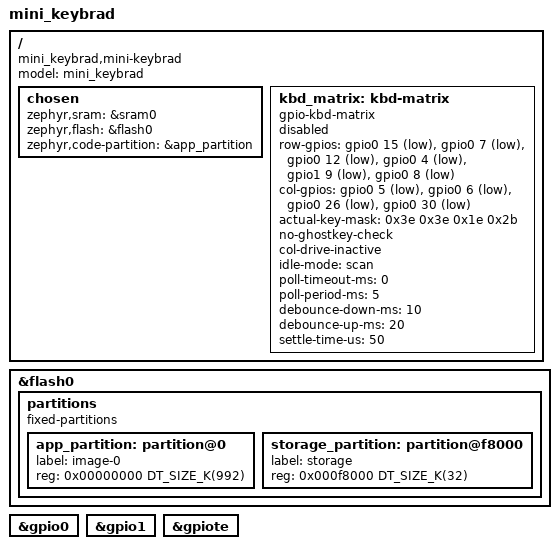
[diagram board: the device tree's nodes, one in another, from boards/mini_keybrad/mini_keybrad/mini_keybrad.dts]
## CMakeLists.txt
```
cmake_minimum_required(VERSION 3.20.0)

list(APPEND BOARD_ROOT "${CMAKE_CURRENT_SOURCE_DIR}")

find_package(Zephyr REQUIRED HINTS $ENV{ZEPHYR_BASE})

project(anjian1)

target_sources(app PRIVATE src/main.c)
```

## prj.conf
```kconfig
CONFIG_GPIO=y
CONFIG_INPUT=y
CONFIG_INPUT_MODE_SYNCHRONOUS=y

CONFIG_LOG=n
CONFIG_BOOT_BANNER=n
CONFIG_NCS_BOOT_BANNER=n
CONFIG_CONSOLE=y
CONFIG_USE_SEGGER_RTT=y
CONFIG_RTT_CONSOLE=y
CONFIG_LOG_BACKEND_UART=n
```

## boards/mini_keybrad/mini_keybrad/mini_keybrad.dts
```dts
/dts-v1/;
#include <nordic/nrf52840_qiaa.dtsi>
#include "mini_keybrad-pinctrl.dtsi"

/ {
	model = "mini_keybrad";
	compatible = "mini_keybrad,mini-keybrad";

	chosen {
		zephyr,sram = &sram0;
		zephyr,flash = &flash0;
		zephyr,code-partition = &app_partition;
	};

	kbd_matrix: kbd-matrix {
		compatible = "gpio-kbd-matrix";
		status = "disabled";

		/*
		 * Temporary pin mapping from the schematic:
		 * ROW0..ROW5: U36.28, U36.22, U36.20, U36.18, U36.17, U36.16
		 * COL0..COL3: U36.15, U36.14, U36.12, U36.10
		 *
		 * Adjust only these row-gpios/col-gpios entries if board bring-up
		 * shows a row or column mismatch.
		 */
		row-gpios = <&gpio0 15 (GPIO_PULL_UP | GPIO_ACTIVE_LOW)>,
			    <&gpio0 7  (GPIO_PULL_UP | GPIO_ACTIVE_LOW)>,
			    <&gpio0 12 (GPIO_PULL_UP | GPIO_ACTIVE_LOW)>,
			    <&gpio0 4  (GPIO_PULL_UP | GPIO_ACTIVE_LOW)>,
			    <&gpio1 9  (GPIO_PULL_UP | GPIO_ACTIVE_LOW)>,
			    <&gpio0 8  (GPIO_PULL_UP | GPIO_ACTIVE_LOW)>;

		col-gpios = <&gpio0 5  GPIO_ACTIVE_LOW>,
			    <&gpio0 6  GPIO_ACTIVE_LOW>,
			    <&gpio0 26 GPIO_ACTIVE_LOW>,
			    <&gpio0 30 GPIO_ACTIVE_LOW>;

		actual-key-mask = <0x3e 0x3e 0x1e 0x2b>;
		no-ghostkey-check;
		col-drive-inactive;
		idle-mode = "scan";
		poll-timeout-ms = <0>;
		poll-period-ms = <5>;
		debounce-down-ms = <10>;
		debounce-up-ms = <20>;
		settle-time-us = <50>;
	};
};

&flash0 {
	partitions {
		compatible = "fixed-partitions";
		#address-cells = <1>;
		#size-cells = <1>;

		app_partition: partition@0 {
			label = "image-0";
			reg = <0x00000000 DT_SIZE_K(992)>;
		};

		storage_partition: partition@f8000 {
			label = "storage";
			reg = <0x000f8000 DT_SIZE_K(32)>;
		};
	};
};

&gpio0 {
	status = "okay";
};

&gpio1 {
	status = "okay";
};

&gpiote {
	status = "okay";
};
```

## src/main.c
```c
#include <zephyr/device.h>
#include <zephyr/drivers/gpio.h>
#include <zephyr/kernel.h>
#include <zephyr/sys/printk.h>
#include <SEGGER_RTT.h>

#define ROW_COUNT 6
#define COL_COUNT 4

struct key_coord {
	uint8_t phys_row;
	uint8_t phys_col;
	uint8_t logical_row;
	uint8_t logical_col;
};

static const struct gpio_dt_spec rows[] = {
	GPIO_DT_SPEC_GET_BY_IDX(DT_NODELABEL(kbd_matrix), row_gpios, 0),
	GPIO_DT_SPEC_GET_BY_IDX(DT_NODELABEL(kbd_matrix), row_gpios, 1),
	GPIO_DT_SPEC_GET_BY_IDX(DT_NODELABEL(kbd_matrix), row_gpios, 2),
	GPIO_DT_SPEC_GET_BY_IDX(DT_NODELABEL(kbd_matrix), row_gpios, 3),
	GPIO_DT_SPEC_GET_BY_IDX(DT_NODELABEL(kbd_matrix), row_gpios, 4),
	GPIO_DT_SPEC_GET_BY_IDX(DT_NODELABEL(kbd_matrix), row_gpios, 5),
};

static const struct gpio_dt_spec cols[] = {
	GPIO_DT_SPEC_GET_BY_IDX(DT_NODELABEL(kbd_matrix), col_gpios, 0),
	GPIO_DT_SPEC_GET_BY_IDX(DT_NODELABEL(kbd_matrix), col_gpios, 1),
	GPIO_DT_SPEC_GET_BY_IDX(DT_NODELABEL(kbd_matrix), col_gpios, 2),
	GPIO_DT_SPEC_GET_BY_IDX(DT_NODELABEL(kbd_matrix), col_gpios, 3),
};

static const struct key_coord key_map[] = {
	{0, 3, 0, 0},
	{1, 0, 1, 0},
	{1, 1, 1, 1},
	{1, 2, 1, 2},
	{1, 3, 1, 3},
	{2, 0, 2, 0},
	{2, 1, 2, 1},
	{2, 2, 2, 2},
	{3, 0, 3, 0},
	{3, 1, 3, 1},
	{3, 2, 3, 2},
	{3, 3, 3, 3},
	{4, 0, 4, 0},
	{4, 1, 4, 1},
	{4, 2, 4, 2},
	{5, 0, 5, 0},
	{5, 1, 5, 1},
	{5, 3, 5, 2},
};

static bool pressed[ROW_COUNT][COL_COUNT];

static const struct key_coord *find_key_coord(int phys_row, int phys_col)
{
	for (size_t i = 0; i < ARRAY_SIZE(key_map); i++) {
		if (key_map[i].phys_row == phys_row &&
		    key_map[i].phys_col == phys_col) {
			return &key_map[i];
		}
	}

	return NULL;
}

static void rtt_print_key(uint8_t row, uint8_t col)
{
	char buf[16];

	snprintk(buf, sizeof(buf), "[%u,%u]\n", row, col);
	SEGGER_RTT_WriteString(0, buf);
}

static int matrix_gpio_init(void)
{
	for (size_t i = 0; i < ARRAY_SIZE(rows); i++) {
		if (!gpio_is_ready_dt(&rows[i])) {
			return -ENODEV;
		}

		int ret = gpio_pin_configure_dt(&rows[i], GPIO_OUTPUT_INACTIVE);

		if (ret != 0) {
			return ret;
		}
	}

	for (size_t i = 0; i < ARRAY_SIZE(cols); i++) {
		if (!gpio_is_ready_dt(&cols[i])) {
			return -ENODEV;
		}

		int ret = gpio_pin_configure_dt(&cols[i], GPIO_INPUT | GPIO_PULL_UP);

		if (ret != 0) {
			return ret;
		}
	}

	return 0;
}

static void matrix_scan_once(void)
{
	for (uint8_t row = 0; row < ROW_COUNT; row++) {
		gpio_pin_set_dt(&rows[row], 1);
		k_busy_wait(50);

		for (uint8_t col = 0; col < COL_COUNT; col++) {
			bool is_down = (gpio_pin_get_dt(&cols[col]) == 1);

			if (is_down && !pressed[row][col]) {
				const struct key_coord *coord = find_key_coord(row, col);

				if (coord != NULL) {
					rtt_print_key(coord->logical_row, coord->logical_col);
				}
			}

			pressed[row][col] = is_down;
		}

		gpio_pin_set_dt(&rows[row], 0);
	}
}

int main(void)
{
	if (matrix_gpio_init() != 0) {
		return 0;
	}

	while (1) {
		matrix_scan_once();
		k_sleep(K_MSEC(5));
	}

	return 0;
}
```
